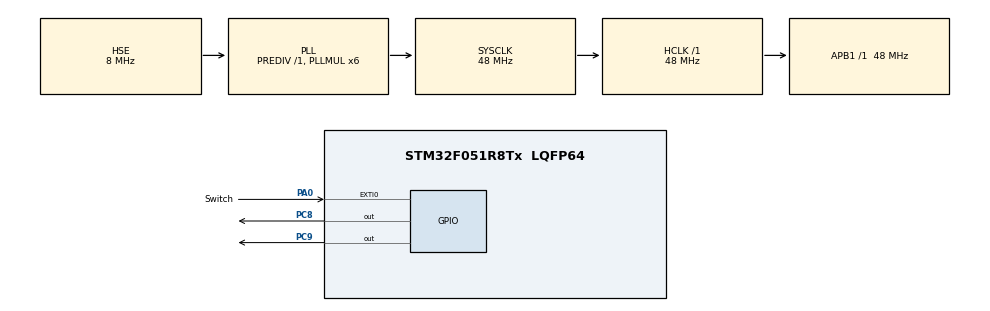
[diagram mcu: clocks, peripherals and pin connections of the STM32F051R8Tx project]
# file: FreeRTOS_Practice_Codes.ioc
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Mcu.Family=STM32F0
Mcu.Name=STM32F051R8Tx
Mcu.Package=LQFP64
NVIC.EXTI0_1_IRQn=true\:0\:0\:false\:false\:true\:true\:true\:true
NVIC.TIM6_DAC_IRQn=true\:2\:0\:true\:false\:true\:true\:true\:true
PA0.GPIO_Label=Switch
PA0.Signal=GPXTI0
PC8.Signal=GPIO_Output
PC9.Signal=GPIO_Output
PF0-OSC_IN.Mode=HSE-External-Clock-Source
PF0-OSC_IN.Signal=RCC_OSC_IN
ProjectManager.HeapSize=0x200
ProjectManager.StackSize=0x400
ProjectManager.TargetToolchain=STM32CubeIDE
RCC.AHBFreq_Value=48000000
RCC.APB1Freq_Value=48000000
RCC.APB1TimFreq_Value=48000000
RCC.HCLKFreq_Value=48000000
RCC.PLLMUL=RCC_PLL_MUL6
RCC.PLLSourceVirtual=RCC_PLLSOURCE_HSE
RCC.SYSCLKFreq_VALUE=48000000
RCC.SYSCLKSource=RCC_SYSCLKSOURCE_PLLCLK
TIM6.AutoReloadPreload=TIM_AUTORELOAD_PRELOAD_ENABLE
TIM6.Period=1600 - 1
TIM6.Prescaler=30000
VP_TIM6_VS_ClockSourceINT.Mode=Enable_Timer
board=custom

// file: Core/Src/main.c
/* USER CODE BEGIN Header */
/**
  ******************************************************************************
  * @file           : main.c
  * @brief          : Main program body
  ******************************************************************************
  * @attention
  *
  * Copyright (c) 2026 STMicroelectronics.
  * All rights reserved.
  *
  * This software is licensed under terms that can be found in the LICENSE file
  * in the root directory of this software component.
  * If no LICENSE file comes with this software, it is provided AS-IS.
  *
  ******************************************************************************
  */
/* USER CODE END Header */
#include "main.h"

TIM_HandleTypeDef htim6;

/* USER CODE BEGIN PV */
uint32_t argTimer = 0;
/* USER CODE END PV */

void SystemClock_Config(void);
static void MX_GPIO_Init(void);
static void MX_TIM6_Init(void);
/* USER CODE BEGIN PFP */
xQueueHandle qHandle;
xSemaphoreHandle SemHand;

typedef struct
{
	uint8_t EventVal;
	uint8_t* EventText;
}EventStrDef;
/* USER CODE END PFP */

int main(void)
{

  /* MCU Configuration--------------------------------------------------------*/

  /* Reset of all peripherals, Initializes the Flash interface and the Systick. */
  HAL_Init();

  /* Configure the system clock */
  SystemClock_Config();

  /* Initialize all configured peripherals */
  MX_GPIO_Init();
  MX_TIM6_Init();

  /* Infinite loop */
  while (1)
  {

  }
}

void SystemClock_Config(void)
{
  RCC_OscInitTypeDef RCC_OscInitStruct = {0};
  RCC_ClkInitTypeDef RCC_ClkInitStruct = {0};

  /** Initializes the RCC Oscillators according to the specified parameters
  * in the RCC_OscInitTypeDef structure.
  */
  RCC_OscInitStruct.OscillatorType = RCC_OSCILLATORTYPE_HSE;
  RCC_OscInitStruct.HSEState = RCC_HSE_BYPASS;
  RCC_OscInitStruct.PLL.PLLState = RCC_PLL_ON;
  RCC_OscInitStruct.PLL.PLLSource = RCC_PLLSOURCE_HSE;
  RCC_OscInitStruct.PLL.PLLMUL = RCC_PLL_MUL6;
  RCC_OscInitStruct.PLL.PREDIV = RCC_PREDIV_DIV1;
  if (HAL_RCC_OscConfig(&RCC_OscInitStruct) != HAL_OK)
  {
    Error_Handler();
  }

  /** Initializes the CPU, AHB and APB buses clocks
  */
  RCC_ClkInitStruct.ClockType = RCC_CLOCKTYPE_HCLK|RCC_CLOCKTYPE_SYSCLK
                              |RCC_CLOCKTYPE_PCLK1;
  RCC_ClkInitStruct.SYSCLKSource = RCC_SYSCLKSOURCE_PLLCLK;
  RCC_ClkInitStruct.AHBCLKDivider = RCC_SYSCLK_DIV1;
  RCC_ClkInitStruct.APB1CLKDivider = RCC_HCLK_DIV1;

  if (HAL_RCC_ClockConfig(&RCC_ClkInitStruct, FLASH_LATENCY_1) != HAL_OK)
  {
    Error_Handler();
  }
}

static void MX_TIM6_Init(void)
{

  TIM_MasterConfigTypeDef sMasterConfig = {0};

  htim6.Instance = TIM6;
  htim6.Init.Prescaler = 30000;
  htim6.Init.CounterMode = TIM_COUNTERMODE_UP;
  htim6.Init.Period = 1600 - 1;
  htim6.Init.AutoReloadPreload = TIM_AUTORELOAD_PRELOAD_ENABLE;
  if (HAL_TIM_Base_Init(&htim6) != HAL_OK)
  {
    Error_Handler();
  }
  sMasterConfig.MasterOutputTrigger = TIM_TRGO_RESET;
  sMasterConfig.MasterSlaveMode = TIM_MASTERSLAVEMODE_DISABLE;
  if (HAL_TIMEx_MasterConfigSynchronization(&htim6, &sMasterConfig) != HAL_OK)
  {
    Error_Handler();
  }

}

static void MX_GPIO_Init(void)
{
  GPIO_InitTypeDef GPIO_InitStruct = {0};

  /* GPIO Ports Clock Enable */
  __HAL_RCC_GPIOF_CLK_ENABLE();
  __HAL_RCC_GPIOA_CLK_ENABLE();
  __HAL_RCC_GPIOC_CLK_ENABLE();

  /*Configure GPIO pin Output Level */
  HAL_GPIO_WritePin(GPIOC, GPIO_PIN_8|GPIO_PIN_9, GPIO_PIN_RESET);

  /*Configure GPIO pin : Switch_Pin */
  GPIO_InitStruct.Pin = Switch_Pin;
  GPIO_InitStruct.Mode = GPIO_MODE_IT_RISING;
  GPIO_InitStruct.Pull = GPIO_NOPULL;
  HAL_GPIO_Init(Switch_GPIO_Port, &GPIO_InitStruct);

  /*Configure GPIO pins : PC8 PC9 */
  GPIO_InitStruct.Pin = GPIO_PIN_8|GPIO_PIN_9;
  GPIO_InitStruct.Mode = GPIO_MODE_OUTPUT_PP;
  GPIO_InitStruct.Pull = GPIO_NOPULL;
  GPIO_InitStruct.Speed = GPIO_SPEED_FREQ_LOW;
  HAL_GPIO_Init(GPIOC, &GPIO_InitStruct);

  /* EXTI interrupt init*/
  HAL_NVIC_SetPriority(EXTI0_1_IRQn, 0, 0);
  HAL_NVIC_EnableIRQ(EXTI0_1_IRQn);

}

void Error_Handler(void)
{
  __disable_irq();
  while (1)
  {
  }
}
